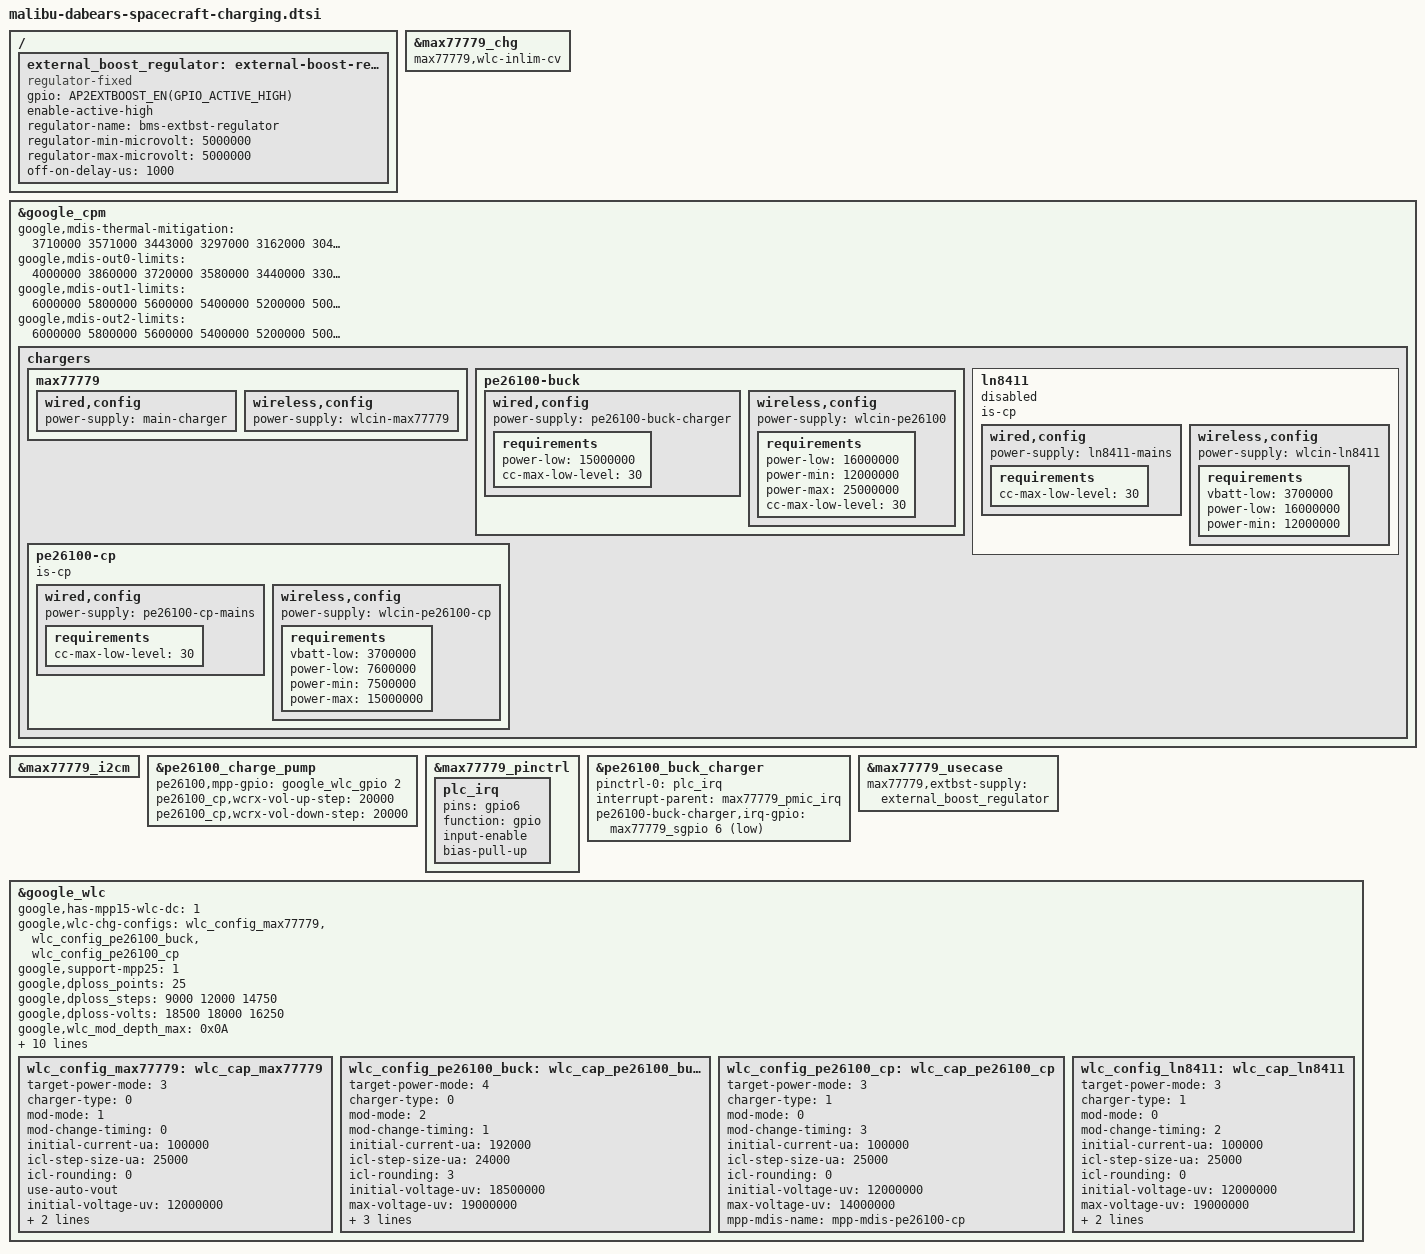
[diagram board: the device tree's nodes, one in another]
// SPDX-License-Identifier: GPL-2.0-only
/*
 * Dabears + Spacecraft charging config for Malibu devices
 *
 * Copyright 2025 Google LLC
 *
 */

/ {
	fragment@charging {
		target-path = "/";
		__overlay__ {
			external_boost_regulator: external-boost-regulator {
				compatible = "regulator-fixed";

				gpio = <AP2EXTBOOST_EN(GPIO_ACTIVE_HIGH)>;
				enable-active-high;

				regulator-name = "bms-extbst-regulator";
				regulator-min-microvolt = <5000000>;
				regulator-max-microvolt = <5000000>;

				off-on-delay-us = <1000>;
			};
		};
	};
};

&max77779_chg {
	max77779,wlc-inlim-cv;
};

&google_cpm {
	/* thermal budgets */
	google,mdis-thermal-mitigation =
	<3710000 3571000 3443000 3297000 3162000 3040000 2918000 2810000 2703000
	 2598000 2493000 2330000 2200000 2080000 1968000 1865000 1770000 1684000
	 1595000 1506000 1444000 1382000 1351000 1320000 1273000 1225000>;
	/* PD+main-charger */
	google,mdis-out0-limits =
	<4000000 3860000 3720000 3580000 3440000 3300000 3160000 3020000 2880000
	 2740000 2600000 2460000 2320000 2180000 2040000 1900000 1760000 1620000
	 1480000 1340000 1200000 1060000 920000  780000  640000  500000>;
	/* PE26100 Buck charger */
	google,mdis-out1-limits =
	<6000000 5800000 5600000 5400000 5200000 5000000 4800000 4600000 4400000
	 4200000 4000000 3800000 3600000 3400000 3200000 3000000 2800000 2600000
	 2400000 2200000 2000000 1800000 1600000 1400000 1200000 1000000>;
	/* PE26100 CP charger */
	google,mdis-out2-limits =
	<6000000 5800000 5600000 5400000 5200000 5000000 4800000 4600000 4400000
	 4200000 4000000 3800000 3600000 3400000 3200000 3000000 2800000 2600000
	 2400000 2200000 2000000 1800000 1600000 1400000 1200000 1000000>;

	chargers {
		max77779 {
			wired,config {
				power-supply = "main-charger";
			};
			wireless,config {
				power-supply = "wlcin-max77779";
			};
		};
		pe26100-buck {
			wired,config {
				power-supply = "pe26100-buck-charger";
				requirements {
					power-low = <15000000>;
					cc-max-low-level = <30>; /* 0.3C */
				};
			};
			wireless,config {
				power-supply = "wlcin-pe26100";
				requirements {
					power-low = <16000000>;
					power-min = <12000000>;
					power-max = <25000000>;
					cc-max-low-level = <30>; /* 0.3C */
				};
			};
		};
		pe26100-cp {
			is-cp;
			wired,config {
				power-supply = "pe26100-cp-mains";
				requirements {
					cc-max-low-level = <30>; /* 0.3C */
				};
			};
			wireless,config {
				power-supply = "wlcin-pe26100-cp";
				requirements {
					vbatt-low = <3700000>;
					power-low = <7600000>;
					power-min = <7500000>;
					power-max = <15000000>;
				};
			};
		};
		ln8411 {
			status = "disabled";
			is-cp;
			wired,config {
				power-supply = "ln8411-mains";
				requirements {
					cc-max-low-level = <30>; /* 0.3C */
				};
			};
			wireless,config {
				power-supply = "wlcin-ln8411";
				requirements {
					vbatt-low = <3700000>;
					power-low = <16000000>;
					power-min = <12000000>;
				};
			};
		};
	};
};

&max77779_i2cm {
	#include "platform/malibu-pe26100-charger.dtsi"
};

&pe26100_charge_pump {
	pe26100,mpp-gpio = <&google_wlc_gpio 2 GPIO_ACTIVE_HIGH>;
	pe26100_cp,wcrx-vol-up-step = <20000>;
	pe26100_cp,wcrx-vol-down-step = <20000>;
};

&max77779_pinctrl {
	plc_irq: plc_irq {
		pins = "gpio6";
		function = "gpio";
		input-enable;
		bias-pull-up;
	};
};

&pe26100_buck_charger {
	pinctrl-0 = <&plc_irq>;
	pinctrl-names = "default";
	interrupt-parent = <&max77779_pmic_irq>;
	/* HYB2IFPMIC_INT_L */
	pe26100-buck-charger,irq-gpio = <&max77779_sgpio 6 GPIO_ACTIVE_LOW>;
 };

&max77779_usecase {
	max77779,extbst-supply = <&external_boost_regulator>;
};

&google_wlc {
	google,has-mpp15-wlc-dc = <1>;
	google,wlc-chg-configs = <&wlc_config_max77779 &wlc_config_pe26100_buck
				  &wlc_config_pe26100_cp>;
	google,support-mpp25 = <1>;
	google,dploss_points = <25>;
	google,dploss_steps = <9000 12000 14750>;
	google,dploss-volts = <18500 18000 16250>;

	google,wlc_mod_depth_max = /bits/ 8 <0x0A>;

	/* Keep as 3 rows of 7 + 1 row of 5  = 26 levels */
	bpp_mdis_pwr = <5000000 4908600 4817200 4725800 4634400 4543000 4451600
			4360200 4268800 4177400 4086000 3994600 3903200 3811800
			3720400 3629000 3537600 3446200 3354800 3263400 3172000
			3080600 2989200 2897800 2806400 2715000>;
	mpp-mdis-max77779 = <15000000 14543440 14086880 13630320 13173760 12717200 12260640
			     11804080 11347520 10890960 10434400  9977840  9521280  9064720
			     8608160  8151600 7695040  7238480  6781920  6325360  5868800
			     5412240  4955680  4499120 4042560  3586000>;
	mpp-mdis-pe26100-buck = <25000000 24000000 23000000 22000000 21000000 20000000 19000000
				 18000000 17000000 16000000 15000000 14000000 13000000 12000000
				 11000000 10000000 9000000  8000000  7000000  5000000  4000000
				 3900000  3800000  3700000 3600000  3500000>;
	mpp-mdis-pe26100-cp = <15000000 15000000 15000000 15000000 15000000 15000000 15000000
			       15000000 15000000 15000000 15000000 14000000 13000000 12000000
			       11000000 10000000 9000000  8000000  7000000  5000000  4000000
			       3900000  3800000  3700000 3600000  3500000>;
	mpp-mdis-ln8411 = <25000000 24500000 23000000 22000000 21000000 20000000 19000000
			   18000000 17000000 16000000 15000000 14000000 13000000 12000000
			   11000000 10000000 9000000  8000000  7000000  5000000  4000000
			   3900000  3800000  3700000 3600000  3500000>;

	wlc_config_max77779: wlc_cap_max77779 {
		target-power-mode = <3>; /* MPP_POWERMODE_NOMINAL */
		charger-type = <0>; /* CHARGER_TYPE_BUCK */
		mod-mode = <1>; /* ASK_MOD_MODE_LOAD_MOD */
		mod-change-timing = <0>; /* ASK_MOD_TIMING_EARLY */
		initial-current-ua = <100000>; /* 100mA */
		icl-step-size-ua = <25000>; /* 25mA */
		icl-rounding = <0>; /* ICL_TARGET_ROUND_UP_WITH_COMP */
		use-auto-vout; /* MPP_AUTO_VOUT_ON */
		initial-voltage-uv = <12000000>; /* 12V */
		max-voltage-uv = <15000000>; /* 12V */
		mpp-mdis-name = "mpp-mdis-max77779";
	};

	wlc_config_pe26100_buck: wlc_cap_pe26100_buck {
		target-power-mode = <4>; /* MPP_POWERMODE_HIGH */
		charger-type = <0>; /* CHARGER_TYPE_BUCK */
		mod-mode = <2>; /* ASK_MOD_MODE_POS_CAP_MOD */
		mod-change-timing = <1>; /* ASK_MOD_TIMING_LATE */
		initial-current-ua = <192000>; /* 192mA */
		icl-step-size-ua = <24000>; /* 24mA */
		icl-rounding = <3>; /* ICL_TARGET_ROUND_NEAREST */
		initial-voltage-uv = <18500000>; /* 18.5V */
		max-voltage-uv = <19000000>; /* 19V */
		mpp25-only;
		exit-by-ept;
		mpp-mdis-name = "mpp-mdis-pe26100-buck";
	};

	wlc_config_pe26100_cp: wlc_cap_pe26100_cp {
		target-power-mode = <3>; /* MPP_POWERMODE_NOMINAL */
		charger-type = <1>; /* CHARGER_TYPE_SWC */
		mod-mode = <0>; /* ASK_MOD_MODE_NEG_CAP_MOD */
		mod-change-timing = <3>; /* ASK_MOD_TIMING_POS_CAP_GPIO */
		initial-current-ua = <100000>; /* 100mA */
		icl-step-size-ua = <25000>; /* 25mA */
		icl-rounding = <0>; /* ICL_TARGET_ROUND_UP_WITH_COMP */
		initial-voltage-uv = <12000000>; /* 12V */
		max-voltage-uv = <14000000>; /* 14V */
		mpp-mdis-name = "mpp-mdis-pe26100-cp";
	};

	wlc_config_ln8411: wlc_cap_ln8411 {
		target-power-mode = <3>; /* MPP_POWERMODE_NOMINAL */
		charger-type = <1>; /* CHARGER_TYPE_SWC */
		mod-mode = <0>; /* ASK_MOD_MODE_NEG_CAP_MOD */
		mod-change-timing = <2>; /* ASK_MOD_TIMING_GPIO */
		initial-current-ua = <100000>; /* 100mA */
		icl-step-size-ua = <25000>; /* 25mA */
		icl-rounding = <0>; /* ICL_TARGET_ROUND_UP_WITH_COMP */
		initial-voltage-uv = <12000000>; /* 12V */
		max-voltage-uv = <19000000>; /* 15V */
		mpp25-only;
		mpp-mdis-name = "mpp-mdis-ln8411";
	};
};
